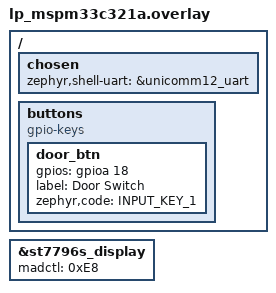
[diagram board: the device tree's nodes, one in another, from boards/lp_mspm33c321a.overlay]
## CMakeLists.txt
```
# SPDX-License-Identifier: Apache-2.0

cmake_minimum_required(VERSION 3.20.0)

# This sample is built for the Waveshare 3.5" RPi LCD (F) panel, which the
# shield provides (ST7796S display + GT911 touch). Default it so a plain
# "west build -b lp_mspm0g3519 ." works; an explicit --shield still overrides.
if(NOT DEFINED SHIELD)
  set(SHIELD waveshare_3_5_rpi_lcd_f)
endif()

find_package(Zephyr REQUIRED HINTS $ENV{ZEPHYR_BASE})
project(ti_washing_machine)

set(UI_DIR ${CMAKE_CURRENT_SOURCE_DIR}/ui)

include(${UI_DIR}/file_list_gen.cmake)
include(${UI_DIR}/user_config.cmake)

target_sources(app PRIVATE
	src/main.c
  src/wash_data.c
	${LV_EDITOR_PROJECT_SOURCES}
)

# The UI uses both same-directory ("washing_machine_gen.h") and root-relative
# ("components/base/card/card_gen.h") includes, so the ui/ root is enough.
target_include_directories(app PRIVATE ${UI_DIR})

# Zephyr's LVGL module adds ${LVGL_DIR}/src/ to the include path (where both
# lvgl.h and lvgl_private.h live), but does NOT add ${LVGL_DIR}/ itself.
# The vendored UI headers include either "lvgl.h" or "lvgl/lvgl.h" depending
# on this guard — setting it picks the flat form that matches what's reachable.
target_compile_definitions(app PRIVATE LV_LVGL_H_INCLUDE_SIMPLE)
```

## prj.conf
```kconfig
# SPDX-License-Identifier: Apache-2.0

CONFIG_DISPLAY=y
CONFIG_LVGL=y
CONFIG_INPUT=y
CONFIG_HWINFO=y

# LVGL rendering for this UI is call-stack heavy; 4K overflows the main thread
# (garbage-PC hard fault). Give it room, and enable a software stack canary
# (the M0+ has no MPU) plus thread names so any overflow is reported clearly.
CONFIG_MAIN_STACK_SIZE=12228
# CONFIG_STACK_SENTINEL=y
CONFIG_THREAD_NAME=y

# RGB565 to match the ST7796S panel.CONFIG_LV_COLOR_DEPTH_16=y

# Cortex-M0+ (ARMv6-M) cannot do unaligned loads. LVGL blends RGB565 image data
# with uint16_t/uint32_t reads, so the compiled-in image arrays must be aligned
# or the blender hard-faults. Default is 1 (byte-aligned) -> force 4.
CONFIG_LV_ATTRIBUTE_MEM_ALIGN_SIZE=4

# Subject/observer API and the "simple" theme the UI is authored against.
CONFIG_LV_USE_OBSERVER=y
CONFIG_LV_USE_THEME_SIMPLE=y

# Widgets instantiated by the washing machine UI.
CONFIG_LV_USE_LABEL=y
CONFIG_LV_USE_IMAGE=y
CONFIG_LV_USE_BUTTON=y
CONFIG_LV_USE_ARC=y
CONFIG_LV_USE_SLIDER=y

# The UI ships its own fonts, but LVGL still needs a built-in default font.
CONFIG_LV_FONT_MONTSERRAT_14=y

# Modest system heap; LVGL's own VDB/mem-pool are placed in sram1 by the
# shield's board conf.
CONFIG_HEAP_MEM_POOL_SIZE=4096

# Vendored UI calls lv_obj_set_name_static() which requires LV_USE_OBJ_NAME.
CONFIG_LV_USE_OBJ_NAME=y

CONFIG_LOG=y
CONFIG_PRINTK=y
CONFIG_LV_Z_POINTER_INPUT_MSGQ_COUNT=64

# Synchronous input: the GT911 poll callback feeds LVGL's own 128-deep pointer
# queue directly, with NO intermediate input-subsystem thread/queue. Avoids
# touch-release events being dropped during long repaints (same reasoning as
# the thermostat sample).
CONFIG_INPUT_MODE_SYNCHRONOUS=y

CONFIG_SENSOR=y
CONFIG_SENSOR_LOG_LEVEL_DBG=y
CONFIG_LV_Z_POINTER_INPUT=y
```

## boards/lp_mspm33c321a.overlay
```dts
/*
 * Copyright (c) 2026 Texas Instruments
 *
 * SPDX-License-Identifier: Apache-2.0
 *
 * Landscape overlay for the ti_washing_machine sample on LP-MSPM0G3519 +
 * waveshare_3_5_rpi_lcd_f shield.  The shield default is portrait (320x480,
 * madctl=0x48).  This overlay rotates the ST7796S to landscape (480x320) and
 * maps GT911 touch coordinates onto the rotated frame.
 *
 * MADCTL byte breakdown (same as waveshare_3_5_tft_touch non-F landscape):
 *   MY=1  MX=1  MV=1  ML=0  BGR=1  MH=0  → 0xE8
 *
 * Touch coordinate pipeline
 * ─────────────────────────
 * The FT5336 driver (used on the non-F waveshare shield) implicitly swaps its
 * X/Y when calling input_touchscreen_report_pos — it passes (col=Y_reg, row=X_reg),
 * so INPUT_ABS_X carries the long axis (0..479) and INPUT_ABS_Y the short axis
 * (0..319).  The GT911 driver does NOT swap: it passes (col=X_reg, row=Y_reg),
 * so INPUT_ABS_X = short (0..319) and INPUT_ABS_Y = long (0..479).
 *
 * Consequence: the lvgl-pointer swap-xy that cancels the FT5336 implicit swap
 * must be REMOVED for GT911.  Instead:
 *  • Override GT911 screen-width/height to landscape (480×320) so the inversion
 *    formula (screen_width - x) uses the correct range for each axis.
 *  • Apply invert-x and invert-y in the LVGL pointer to mirror both axes —
 *    this is the same net effect as the non-F shield's double-swap + 2 inverts.
 */

#include <zephyr/dt-bindings/i2c/i2c.h>
#include <zephyr/dt-bindings/gpio/gpio.h>
#include <zephyr/dt-bindings/input/input-event-codes.h>

/ {
	chosen {
		zephyr,shell-uart = &unicomm12_uart;
	};
};

&st7796s_display {
	madctl = <0xE8>;
};


/ {
	buttons: buttons {
		compatible = "gpio-keys";
		status = "okay";

		/* Door reed switch / momentary button; verify polarity against board schematic */
		door_btn: door_btn {
			gpios = <&gpioa 18 (GPIO_ACTIVE_HIGH | GPIO_PULL_DOWN)>;
			label = "Door Switch";
			zephyr,code = <INPUT_KEY_1>;
			status = "okay";
		};
	};
};

// &unicomm13_0 {
// 	status = "okay";
// };

// &unicomm13_0_i2c {
// 	status = "okay";
// 	pinctrl-0 = <&uc13_0_sda_pb12 &uc13_0_scl_pb13>;
// 	pinctrl-names = "default";

// 	light: opt3001-light@44 {
// 		status = "okay";
// 		compatible = "ti,opt3001";
// 		reg = <0x44>;
// 		int-gpios = <&gpioa 15 (GPIO_ACTIVE_LOW | GPIO_PULL_UP)>;
// 	};
// };
```

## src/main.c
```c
/*
 * Copyright (c) 2026 Texas Instruments
 *
 * SPDX-License-Identifier: Apache-2.0
 *
 * Runs the vendored LVGL "washing machine" UI (see ui/, provenance in README.rst)
 * on a Zephyr display + touch. Zephyr auto-initializes LVGL and registers the
 * display/pointer devices via SYS_INIT (CONFIG_LV_Z_AUTO_INIT), so by the time
 * main() runs lv_init() has already happened and we only have to build the UI
 * and pump lv_timer_handler().
 */

#include <zephyr/device.h>
#include <zephyr/devicetree.h>
#include <zephyr/drivers/display.h>
#include <zephyr/drivers/hwinfo.h>
#include <zephyr/init.h>
#include <zephyr/kernel.h>
#include <lvgl.h>
#include <zephyr/drivers/sensor.h>
#include <stdio.h>
// #include <lv_demos.h>

#include "ti_washing_machine.h"
#include "wash_data.h"
#include "wash_sensor.h"

#define LOG_LEVEL CONFIG_LOG_DEFAULT_LEVEL
#include <zephyr/logging/log.h>
LOG_MODULE_REGISTER(app);



// #define WASH_SENSOR_POLL_MS   100

// /* Only lp_mspm33c321a's overlay instantiates the APDS9960 node; other boards
//  * supported by this sample (e.g. lp_mspm0g3519) have no such node, and
//  * DEVICE_DT_GET_ONE() requires the node to exist at compile time. */


// static const struct device * prox_dev;
// static lv_timer_t * sensor_timer;

// // Define your operational environment bounds (in Lux)
// #define LUX_DARK_THRESHOLD   10   // Below this is considered "Full Dark"
// #define LUX_BRIGHT_THRESHOLD 500  // Above this is considered "Bright Enough"

// // Define your target water fill levels (e.g., in centimeters or percentage 0-100)
// #define WATER_LEVEL_MIN      10   // Keep a minimum baseline level
// #define WATER_LEVEL_MAX      90   // Safety ceiling to prevent overflow

// static int calculate_water_target(int current_lux) 
// {
//     // 1. Safety Check / Boundary Clamping
//     if (current_lux <= LUX_DARK_THRESHOLD) {
//         return WATER_LEVEL_MAX; // Completely dark -> fill to max safety limit
//     }
//     if (current_lux >= LUX_BRIGHT_THRESHOLD) {
//         return WATER_LEVEL_MIN; // Bright enough -> drop to min baseline
//     }

//     // 2. Linear Inversion Mapping
//     // Formula scales linearly between your dark/bright thresholds
//     int light_fraction = (current_lux - LUX_DARK_THRESHOLD) / (LUX_BRIGHT_THRESHOLD - LUX_DARK_THRESHOLD);
    
//     // Invert it: as light_fraction goes 0.0 -> 1.0, water target goes MAX -> MIN
//     int target_level = WATER_LEVEL_MAX - (light_fraction * (WATER_LEVEL_MAX - WATER_LEVEL_MIN));

//     return target_level;
// }

// static void process_sensor_data(const struct device *opt3001_dev) 
// {
//     struct sensor_value lux_val;
    
//     // Fetch data from Zephyr sensor API
//     if (sensor_sample_fetch(opt3001_dev) == 0) {
//         sensor_channel_get(opt3001_dev, SENSOR_CHAN_LIGHT, &lux_val);
                
//         // Calculate the target
//         int water_target = calculate_water_target(lux_val.val1);
        
//         lv_subject_set_int(&subject_water_level, water_target);
        
//         printk("Current Light: %d lux -> Target Water Level: %d\n", 
//                 lux_val.val1, water_target);

            
//     }
//             printk("rimercallback\n");
// }

// static void wash_sensor_timer_cb(lv_timer_t * timer)
// {
//     LV_UNUSED(timer);

    
//     process_sensor_data(prox_dev);

// }


int main(void)
{
	const struct device *display_dev = DEVICE_DT_GET(DT_CHOSEN(zephyr_display));
	int ret;

	printk("Washing machine demo starting on %s", display_dev->name);

	if (!device_is_ready(display_dev)) {
		LOG_ERR("Display device not ready");
		return 0;
	}

	lv_display_set_rotation(lv_display_get_default(), LV_DISPLAY_ROTATION_90);
    
	/*
	prox_dev = DEVICE_DT_GET_ONE(ti_opt3001);
    if(!device_is_ready(prox_dev)) {
        printk("ti_opt3001 not ready, subject_water_level sensor input disabled");
        return 0;
    }

	printk("Sensor monitor initialized (HDC2080 + RTC)");    

    sensor_timer = lv_timer_create(wash_sensor_timer_cb, WASH_SENSOR_POLL_MS, NULL);
	*/

	/* Build the washing machine UI (subjects, screens, logic + simulator) and
	 * load the home screen. Assets are compiled in, so the asset-path
	 * argument is unused on this target. */
	ti_washing_machine_init("A:");

	/* Render one frame, then enable the panel. */
	lv_timer_handler();
	ret = display_blanking_off(display_dev);
	if (ret < 0 && ret != -ENOSYS) {
		LOG_ERR("Failed to turn display blanking off (%d)", ret);
		return 0;
	}

	while (1) {
		uint32_t sleep_ms = lv_timer_handler();

		if (sleep_ms == LV_NO_TIMER_READY) {
			sleep_ms = LV_DEF_REFR_PERIOD;
		}
		k_sleep(K_MSEC(sleep_ms));
	}

	return 0;
}
```

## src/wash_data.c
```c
#include <zephyr/device.h>
#include <zephyr/input/input.h>
#include <zephyr/dt-bindings/input/input-event-codes.h>

#include "ti_washing_machine.h"

/* Only lp_mspm33c321a's overlay instantiates door_btn; other boards
 * supported by this sample have no such node. */
#if DT_NODE_EXISTS(DT_NODELABEL(door_btn))

static void wash_door_cb(struct input_event * evt, void * user_data)
{
    LV_UNUSED(user_data);

    int curr_state = lv_subject_get_int(&subject_door);
    if(evt->code != INPUT_KEY_1) return;

    lv_subject_set_int(&subject_door, 1 - curr_state);
}

INPUT_CALLBACK_DEFINE(DEVICE_DT_GET(DT_NODELABEL(buttons)), wash_door_cb, NULL);

void wash_door_init(void)
{
    /* Callback is statically registered via INPUT_CALLBACK_DEFINE above. */
}

#else /* !DT_NODE_EXISTS(DT_NODELABEL(door_btn)) */

void wash_door_init(void)
{
    /* No door_btn node on this board target; subject_door stays UI-driven. */
}

#endif
```

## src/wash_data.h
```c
/* wash_door - reflects the PA18 door switch onto subject_door. */
#ifndef WASH_DOOR_H
#define WASH_DOOR_H

/** Register the module. Call after washing_machine_init_gen(). */
void wash_door_init(void);

#endif /* WASH_DOOR_H */
 
```

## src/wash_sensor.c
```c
#include "wash_sensor.h"

#include <zephyr/device.h>
#include <zephyr/drivers/sensor.h>
#include <zephyr/logging/log.h>

#include "ti_washing_machine.h"

LOG_MODULE_REGISTER(wash_sensor, CONFIG_LOG_DEFAULT_LEVEL);

#define WASH_SENSOR_POLL_MS   100

/* Only lp_mspm33c321a's overlay instantiates the APDS9960 node; other boards
 * supported by this sample (e.g. lp_mspm0g3519) have no such node, and
 * DEVICE_DT_GET_ONE() requires the node to exist at compile time. */


static const struct device * prox_dev;
static lv_timer_t * sensor_timer;

// Define your operational environment bounds (in Lux)
#define LUX_DARK_THRESHOLD   10   // Below this is considered "Full Dark"
#define LUX_BRIGHT_THRESHOLD 500  // Above this is considered "Bright Enough"

// Define your target water fill levels (e.g., in centimeters or percentage 0-100)
#define WATER_LEVEL_MIN      10   // Keep a minimum baseline level
#define WATER_LEVEL_MAX      90   // Safety ceiling to prevent overflow

static int calculate_water_target(int current_lux) 
{
    // 1. Safety Check / Boundary Clamping
    if (current_lux <= LUX_DARK_THRESHOLD) {
        return WATER_LEVEL_MAX; // Completely dark -> fill to max safety limit
    }
    if (current_lux >= LUX_BRIGHT_THRESHOLD) {
        return WATER_LEVEL_MIN; // Bright enough -> drop to min baseline
    }

    // 2. Linear Inversion Mapping
    // Formula scales linearly between your dark/bright thresholds
    int light_fraction = (current_lux - LUX_DARK_THRESHOLD) / (LUX_BRIGHT_THRESHOLD - LUX_DARK_THRESHOLD);
    
    // Invert it: as light_fraction goes 0.0 -> 1.0, water target goes MAX -> MIN
    int target_level = WATER_LEVEL_MAX - (light_fraction * (WATER_LEVEL_MAX - WATER_LEVEL_MIN));

    return target_level;
}

static void process_sensor_data(const struct device *opt3001_dev)
{
    struct sensor_value lux_val;

    // Fetch data from Zephyr sensor API
    if (sensor_sample_fetch(opt3001_dev) == 0) {
        sensor_channel_get(opt3001_dev, SENSOR_CHAN_LIGHT, &lux_val);

        // Calculate the target
        int water_target = calculate_water_target(lux_val.val1);

        lv_subject_set_int(&subject_water_level, water_target);

        LOG_INF("Current Light: %d lux -> Target Water Level: %d",
                lux_val.val1, water_target);
    }
}

static void wash_sensor_timer_cb(lv_timer_t * timer)
{
    LV_UNUSED(timer);

    
    process_sensor_data(prox_dev);

    // if(sensor_sample_fetch(prox_dev) < 0) return;
    // if(sensor_channel_get(prox_dev, SENSOR_CHAN_LIGHT, &prox) < 0) return;

    
    

    // int32_t level = (prox.val1 * 100) / APDS9960_PROX_MAX;
    // if(level > 100) level = 100;
    // if(level < 0) level = 0;

    // lv_subject_set_int(&subject_water_level, level);
}

void wash_sensor_init(void)
{
    prox_dev = DEVICE_DT_GET_ONE(ti_opt3001);
    if(!device_is_ready(prox_dev)) {
        LV_LOG_WARN("ti_opt3001 not ready, subject_water_level sensor input disabled");
        return;
    }

	    printk("Sensor monitor initialized (HDC2080 + RTC)");    

    sensor_timer = lv_timer_create(wash_sensor_timer_cb, WASH_SENSOR_POLL_MS, NULL);
}
```

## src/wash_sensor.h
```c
/* wash_sensor - polls the APDS9960 proximity channel onto subject_water_level. */
#ifndef WASH_SENSOR_H
#define WASH_SENSOR_H

/** Register the module. Call after washing_machine_init_gen(). */
void wash_sensor_init(void);

#endif /* WASH_SENSOR_H */
```
